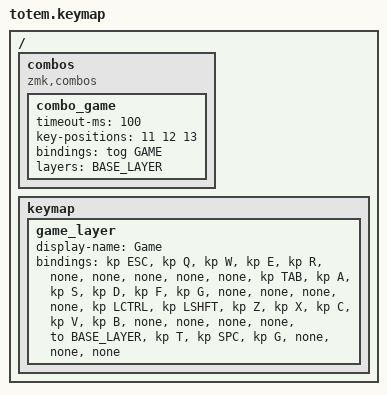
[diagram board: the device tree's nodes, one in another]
// Totem 38-key layout: strips outer columns from rows 1-2, keeps them for row 3
#define SELENIUM_KEYMAP_BINDINGS(LOUT1,  LROW1,  RROW1,  ROUT1, \
                                 LOUT2,  LROW2,  RROW2,  ROUT2, \
                                 LOUT3,  LROW3,  RROW3,  ROUT3, \
                                 LT1, LT2, LT3,  RT3, RT2, RT1) \
          LROW1   RROW1       \
          LROW2   RROW2       \
    LOUT3 LROW3   RROW3 ROUT3 \
    LT1 LT2 LT3   RT3 RT2 RT1

// Host: Ergol layout on Linux
// Variant: Vim navigation
#define KB_LAYOUT_ERGOL
#define LINUX
#define VIM_NAVIGATION

#include <aekeynox/selenium.keymap>

#define GAME EXTRA_LAYERS_START_INDEX

/ {
    combos {
        compatible = "zmk,combos";
        combo_game {
            timeout-ms = <100>;
            key-positions = <11 12 13>; // SDF on the home row
            bindings = <&tog GAME>;
            layers = <BASE_LAYER>;
        };
    };

    keymap {
        // 7. Game layer -- raw QWERTY for gaming, toggle back with SDF combo
        game_layer: game_layer {
            display-name = "Game";
            bindings = <
// ╷           ╷           ╷           ╷           ╷           ╷   ╷           ╷           ╷           ╷           ╷           ╷
                &kp ESC     &kp Q       &kp W       &kp E       &kp R           &none       &none       &none       &none       &none
                &kp TAB     &kp A       &kp S       &kp D       &kp F           &kp G       &none       &none       &none       &none
    &kp LCTRL   &kp LSHFT   &kp Z       &kp X       &kp C       &kp V           &kp B       &none       &none       &none       &none       &to BASE_LAYER
                                        &kp T       &kp SPC     &kp G           &none       &none       &none
            >;
        };
    };
};
